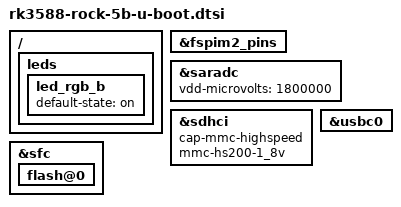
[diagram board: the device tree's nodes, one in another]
// SPDX-License-Identifier: (GPL-2.0+ OR MIT)
/*
 * Copyright (c) 2023 Collabora Ltd.
 */

#include <dt-bindings/usb/pd.h>
#include "rk3588-u-boot.dtsi"

/ {
	leds {
		led_rgb_b {
			default-state = "on";
		};
	};
};

&fspim2_pins {
	bootph-pre-ram;
	bootph-some-ram;
};

&saradc {
	bootph-pre-ram;
	vdd-microvolts = <1800000>;
};

&sdhci {
	cap-mmc-highspeed;
	mmc-hs200-1_8v;
};

&sfc {
	flash@0 {
		bootph-pre-ram;
		bootph-some-ram;
	};
};

&usbc0 {
	status = "okay";
};
